# ISD91200B_v1 register map
File version: 1.0
Registers are 32-bit, read-write, reset 0x0 unless marked. A register's access mark holds for its fields unless they carry their own. Offsets are from the block's base; [hi:lo] are bit positions.

## ANA — ANA Register Map
Base 0x40080000
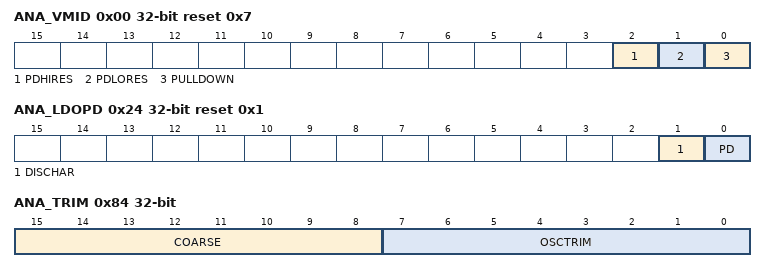
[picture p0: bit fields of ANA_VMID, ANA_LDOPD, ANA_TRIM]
0x00 ANA_VMID reset 0x7 — VMID Reference Control Register
  [2] PDHIRES — Power Down High (360kΩ) Resistance Reference
    0=Connect the High Resistance reference to VMID. Use this setting for minimum power consumption; 1=The High Resistance reference is disconnected from VMID. Default power down and reset condition
  [1] PDLORES — Power Down Low (4.8kΩ) Resistance Reference
    0=Connect the Low Resistance reference to VMID. Use this setting for fast power up of VMID. Can be turned off after 50ms to save power; 1=The Low Resistance reference is disconnected from VMID. Default power down and reset condition
  [0] PULLDOWN — VMID Pulldown
    0=Release VMID pin for reference operation; 1=Pull VMID pin to ground. Default power down and reset condition
0x20 ANA_LDOSEL — LDO Voltage Select Register
  [2:0] LDOSEL — Select LDO Output Voltage. Note that maximum I/O pad operation speed only specified for voltage >2.4V.
    0=1.8V; 1=2.4V; 2=2.5V; 3=2.7V; 4=3.0V; 5=3.3V; 6=1.5V; 7=1.7V
0x24 ANA_LDOPD reset 0x1 — LDO Power Down Register
  [1] DISCHAR — Discharge
    0=Don't discharge VD33; 1=Switch discharge resistor to VD33
  [0] PD — Power Down LDO. When powered down no current delivered to VD33.
    0=Enable LDO; 1=Power Down
0x28 ANA_MICBSEL — Microphone Bias Voltage Level Selection
0x2C ANA_MICBEN reset 0x1 — Microphone Bias Enable
0x84 ANA_TRIM (reset mask 0xFFFF0000) — Oscillator Trim Register
  [15:8] COARSE — COARSE. Current COARSE range setting of the oscillator. Read Only
  [7:0] OSCTRIM — Oscillator Trim. Reads current oscillator trim setting. Read Only.
0x94 ANA_FQMMCTL reset 0x1 — Frequency Measurement Control Register
  [15:0] FQMMCNT — Frequency Measurement Count. Maximum resolution of measurement is Fref /(CYCLESEL+1)*2 Hz
0x98 ANA_FQMMCNT — Frequency Measurement Count Register
0x9C ANA_FQMMCYC — Frequency Measurement Cycle Register
  [23:0] FQMMCYC — Frequency Measurement Cycles

## ALC — ALC Register Map
Base 0x400B0090
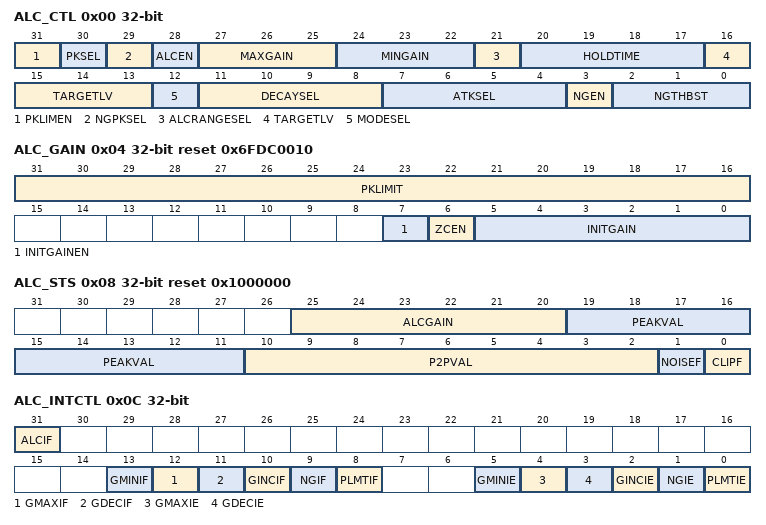
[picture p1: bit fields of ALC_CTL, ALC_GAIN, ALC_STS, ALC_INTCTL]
0x00 ALC_CTL — ALC Control Register
  [31] PKLIMEN — ALC Peak Limiter Enable. Default is "0", Please set as "1"
  [30] PKSEL — ALC Gain Peak Detector Select
    0=use absolute peak value for ALC training (default); 1=use peak-to-peak value for ALC training
  [29] NGPKSEL — ALC Noise Gate Peak Detector Select
    0=use peak-to-peak value for noise gate threshold determination (default); 1=use absolute peak value for noise gate threshold determination
  [28] ALCEN — ALC Select
    0=ALC disabled (default); 1=ALC enabled
  [27:25] MAXGAIN — ALC Maximum Gain
    0=-6.75 dB; 1=-0.75 dB; 2=+5.25 dB; 3=+11.25 dB; 4=+17.25 dB; 5=+23.25 dB; 6=+29.25 dB; 7=+35.25 dB
  [24:22] MINGAIN — ALC Minimum Gain
    0=-12 dB; 1=-6 dB; 2=0 dB; 3=6 dB; 4=12 dB; 5=18 dB; 6=24 dB; 7=30 dB
  [21] ALCRANGESEL — ALC Target range selection
    0=ALC target range -28.5~ -6dB; 1=ALC target range -22.5 ~-1.5dB
  [20:17] HOLDTIME — ALC Hold Time
  [16:13] TARGETLV — ALC Target Level
    0=-28.5 dB; 1=-27 dB; 2=-25.5 dB; 3=-24 dB; 4=-22.5 dB; 5=-21 dB; 6=-19.5 dB; 7=-18 dB; 8=-16.5 dB; 9=-15 dB; 10=-13.5 dB; 11=-12 dB; 12=-10.5 dB; 13=-9 dB; 14=-7.5 dB; 15=-6 dB
  [12] MODESEL — ALC Mode
    0=ALC normal operation mode; 1=ALC limiter mode
  [11:8] DECAYSEL — ALC Decay Time (Value: 0~10)
  [7:4] ATKSEL — ALC Attack Time (Value: 0~10)
  [3] NGEN — Noise Gate Enable
    0=Noise gate disabled; 1=Noise gate enabled
  [2:0] NGTHBST — Noise Gate Threshold. 000 --- -39dB. 001--- -45dB. 010---- -51dB. 011 --- -57dB. 100 --- -63dB. 101 --- -69dB. 110 --- -75dB. 111 --- -81dB
0x04 ALC_GAIN reset 0x6FDC0010 — ALC GAIN Control Register
  [31:16] PKLIMIT — ALC Peak Limiter Threshold. Full scale - 0x7fff. Default value is 0x6fdc - 87.5% of full scale
  [7] INITGAINEN — ALC Update Initial Gain
    0=ALC PGA GAIN load automatic calculating gain; 1=ALC PGA GAIN load ALCINIT_GAIN
  [6] ZCEN — ALC Zero Crossing Enable
    0=zero crossing disabled; 1=zero crossing enabled when update gain
  [5:0] INITGAIN — ALC Initial Gain. Set ALC initial gain. Selects the PGA gain setting from -12dB to 35.25dB in 0.75dB step size. 0x00 is lowest gain setting at -12dB and 0x3F is largest gain at 35.25dB
0x08 ALC_STS reset 0x1000000 — ALC Status Register
  [25:20] ALCGAIN — ALC GAIN. Current ADC gain setting
  [19:11] PEAKVAL — Peak Value. 9 MSBs of measured absolute peak value
  [10:2] P2PVAL — Peak-to-peak Value. 9 MSBs of measured peak-to-peak value
  [1] NOISEF — Noise Flag. Asserted when signal level is detected to be below NGTHBST
  [0] CLIPF — Clipping Flag. Asserted when signal level is detected to be above 87.5% of full scale
0x0C ALC_INTCTL — ALC Interrupt Control Register
  [31] ALCIF — ALC Interrupt flag. This interrupt flag asserts whenever the interrupt is enabled and the PGA gain is updated, either through an ALC change with the ALC enabled or through a PGA gain write with the ALC disabled. Write a 1 to this register to clear.
  [13] GMINIF — GAIN less than minimum GAIN interrupt flag.
  [12] GMAXIF — GAIN more than maximum GAIN interrupt flag.
  [11] GDECIF — GAIN Decrease interrupt flag
  [10] GINCIF — GAIN Increase interrupt flag
  [9] NGIF — ALC noise gating interrupt flag
  [8] PLMTIF — ALC Peak limiting Interrupt flag
  [5] GMINIE — GAIN less than minimum GAIN interrupt enable control
  [4] GMAXIE — GAIN more than maximum GAIN interrupt enable control
  [3] GDECIE — GAIN Decrease interrupt enable control
  [2] GINCIE — GAIN Increase interrupt enable control
  [1] NGIE — ALC noise gating interrupt enable control
  [0] PLMTIE — ALC Peak limiting Interrupt enable control
